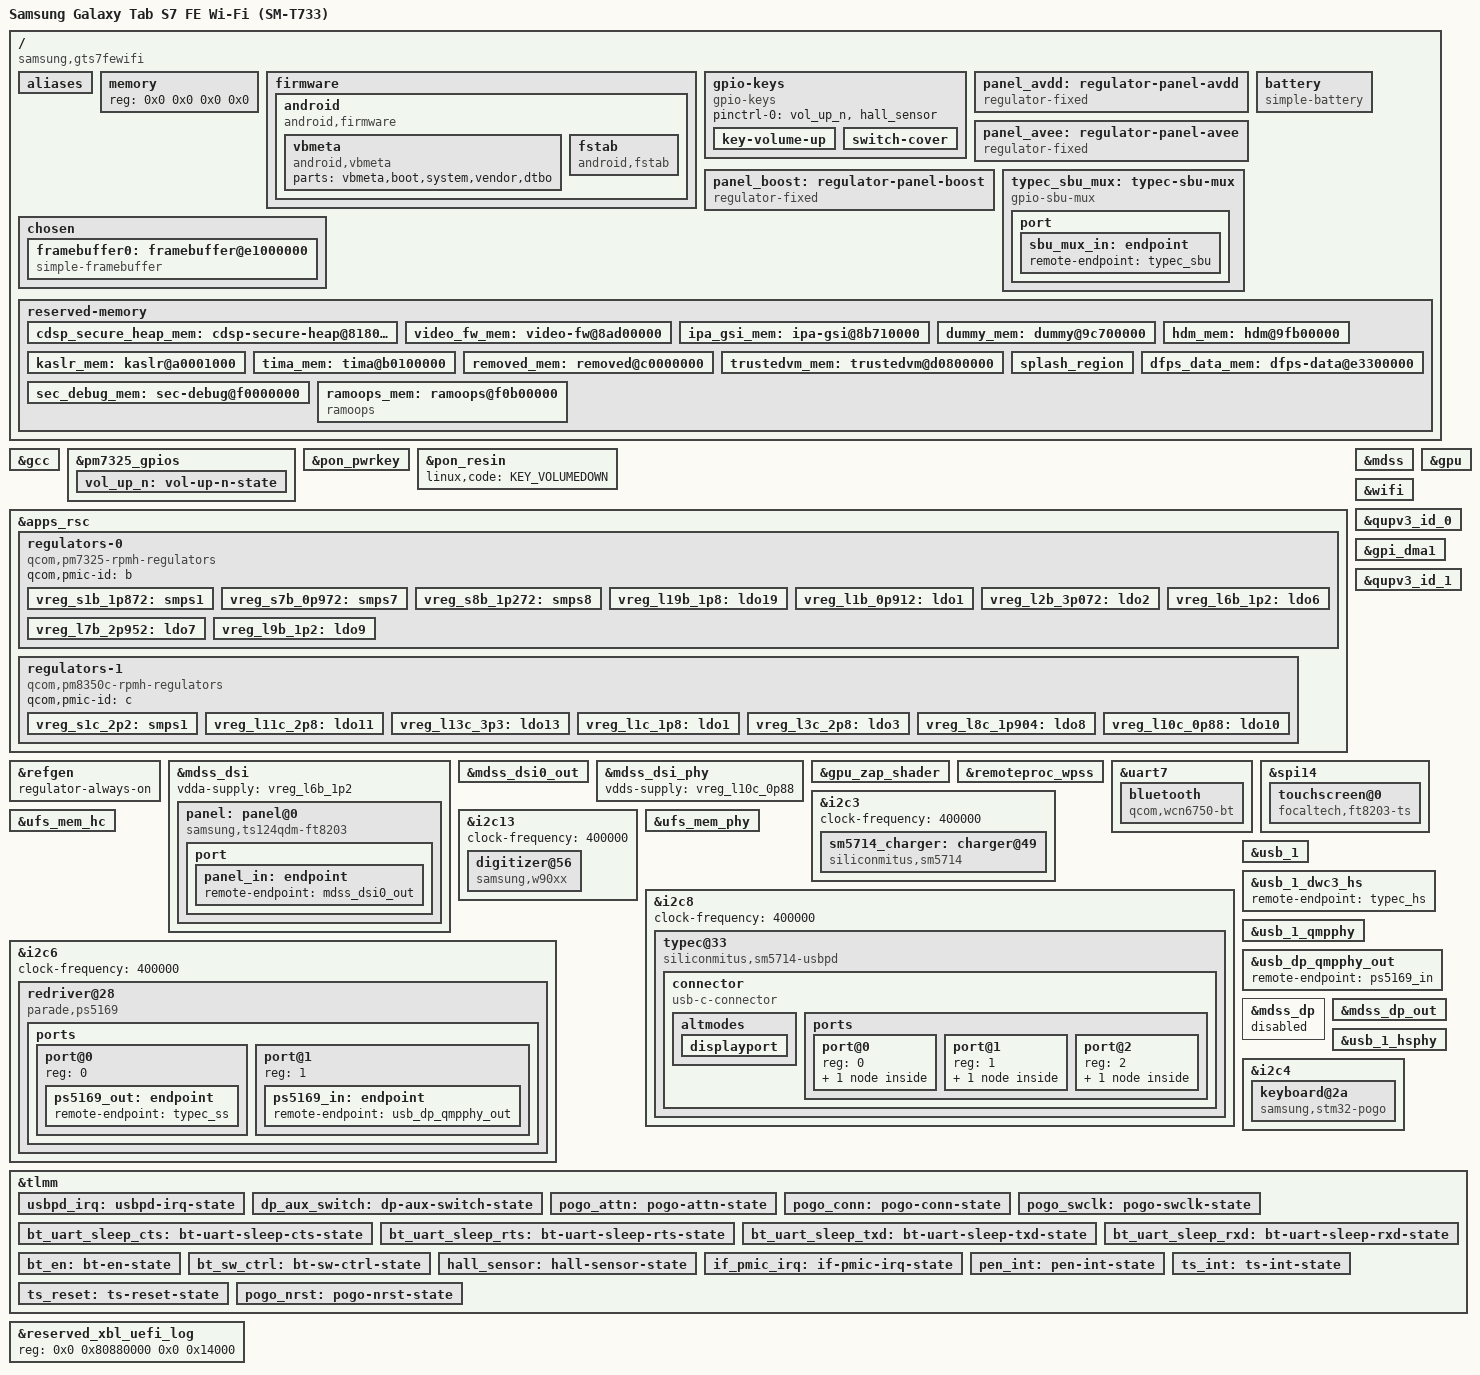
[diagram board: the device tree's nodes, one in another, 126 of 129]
// SPDX-License-Identifier: BSD-3-Clause
/*
 * Samsung Galaxy Tab S7 FE Wi-Fi (SM-T733, "gts7fewifi"), Snapdragon 778G
 * (SM7325, Qualcomm's "yupik").
 *
 * Bring-up: the kernel log on the display the bootloader left on
 * (simple-framebuffer, ramoops), the buttons, (stage 2) the regulators,
 * UFS storage, USB in device mode and the Book Cover Keyboard, and (stage 4)
 * the display driven by msm (its panel, a TS124QDM with a FocalTech FT8203,
 * and the brightness) and the touchscreen, (stage 6) Wi-Fi and Bluetooth
 * (WCN6750), (stage 5) battery and charging, (stage 7) the GPU and
 * (stage 8) the S Pen and the cover's hall sensor. USB-C dual role and
 * DisplayPort are wired through SM5714, PS5169 and the SBU GPIO mux.
 * Everything else in sm7325.dtsi stays disabled until its board wiring is
 * known. The Wi-Fi/Bluetooth and GPU wiring is the same as on the other
 * SM7325/QCM6490 devices (Nothing Phone (1), Fairphone 5).
 *
 * Values come from the stock firmware T733XXS9DYF1 (scripts/inspect-stock.sh):
 * the base tree in vendor_boot.img and Samsung's board overlay in dtbo.img
 * ("Samsung GTS7FEWIFI PROJECT").
 */

/dts-v1/;

#include <dt-bindings/arm/qcom,ids.h>
#include <dt-bindings/gpio/gpio.h>
#include <dt-bindings/input/input.h>
#include <dt-bindings/pinctrl/qcom,pmic-gpio.h>
#include <dt-bindings/regulator/qcom,rpmh-regulator.h>
#include <dt-bindings/usb/pd.h>

#include "sm7325.dtsi"
#include "pm7325.dtsi"
#include "pmk8350.dtsi" /* PMK7325 */

/ {
	model = "Samsung Galaxy Tab S7 FE Wi-Fi (SM-T733)";
	compatible = "samsung,gts7fewifi", "qcom,sm7325";
	chassis-type = "tablet";

	/*
	 * The bootloader picks the tree by these. The same as the stock base
	 * tree ("Yupik SoC"): SM7325 and SoC id 0x203, a variant mainline's
	 * qcom,ids.h has no name for; board-id 0 0 as the base tree has (the
	 * board's own <0x22 rev> are in the dtbo overlays, which jk_os keeps
	 * empty: targets/devices/tablet/samsung-gts7fe/dtbo). dtbo-version, as
	 * the stock base tree has it, matches the overlays'.
	 */
	qcom,msm-id = <QCOM_ID_SM7325 0x10000>, <0x203 0x10000>;
	qcom,board-id = <0 0>;
	dtbo-version = <0>;

	/*
	 * Nodes Samsung's bootloader updates before starting the kernel, under
	 * the names it looks them up by (its strings: "/memory",
	 * "/firmware/android/fstab"), as stock's tree has them. With
	 * mainline's (memory@80000000, no android node) our tree fell back to
	 * Download mode where stock's didn't. It fills in the memory size.
	 */
	/delete-node/ memory@80000000;

	/*
	 * Bluetooth's UART needs a line number, which qcom_geni_serial takes
	 * from its serial alias ("Invalid line -19" without it).
	 */
	aliases {
		bluetooth0 = &bluetooth;
		serial1 = &uart7;
		wifi0 = &wifi;
	};

	memory {
		device_type = "memory";
		reg = <0x0 0x0 0x0 0x0>;
	};

	firmware {
		android {
			compatible = "android,firmware";

			vbmeta {
				compatible = "android,vbmeta";
				parts = "vbmeta,boot,system,vendor,dtbo";
			};

			fstab {
				compatible = "android,fstab";
			};
		};
	};

	/*
	 * Volume up, as stock has it (Samsung's gpio_keys: PM7325 GPIO 6,
	 * active low). Volume down and power are the PMIC's own keys (PON
	 * resin and pwrkey, below). U-Boot's menu uses all three.
	 */
	gpio-keys {
		compatible = "gpio-keys";
		pinctrl-0 = <&vol_up_n>, <&hall_sensor>;
		pinctrl-names = "default";

		key-volume-up {
			label = "Volume Up";
			gpios = <&pm7325_gpios 6 GPIO_ACTIVE_LOW>;
			linux,code = <KEY_VOLUMEUP>;
			debounce-interval = <15>;
		};

		/*
		 * The Book Cover's magnet (stock: hall_ic's hall, GPIO 101,
		 * active low, event 0x15 = SW_LID).
		 */
		switch-cover {
			label = "Cover";
			gpios = <&tlmm 101 GPIO_ACTIVE_LOW>;
			linux,input-type = <EV_SW>;
			linux,code = <SW_LID>;
			linux,can-disable;
			debounce-interval = <150>;
			wakeup-source;
		};
	};

	/*
	 * The panel's bias rails (stock: Samsung's fixed_regulator nodes, GPIO
	 * enables): panel_buck_en and panel_buck_en2 switch the ISL98608 that
	 * makes the TFT's positive and negative supplies, panel_boost_en the
	 * MAX77816 behind the backlight. The bootloader sets those chips up
	 * over I2C and switches the rails on; switching them off would lose
	 * that setup (msm's display off then hangs the DSI link), so they stay
	 * on, and the panel only sleeps when the display is off.
	 */
	panel_avdd: regulator-panel-avdd {
		compatible = "regulator-fixed";
		regulator-name = "panel_avdd";
		gpio = <&tlmm 96 GPIO_ACTIVE_HIGH>;
		enable-active-high;
		regulator-boot-on;
		regulator-always-on;
	};

	panel_avee: regulator-panel-avee {
		compatible = "regulator-fixed";
		regulator-name = "panel_avee";
		gpio = <&tlmm 97 GPIO_ACTIVE_HIGH>;
		enable-active-high;
		regulator-boot-on;
		regulator-always-on;
	};

	panel_boost: regulator-panel-boost {
		compatible = "regulator-fixed";
		regulator-name = "panel_boost";
		gpio = <&tlmm 98 GPIO_ACTIVE_HIGH>;
		enable-active-high;
		regulator-boot-on;
		regulator-always-on;
	};

	/* Stock AUX_EN_N GPIO100 and AUX_SEL GPIO99. */
	typec_sbu_mux: typec-sbu-mux {
		compatible = "gpio-sbu-mux";
		enable-gpios = <&tlmm 100 GPIO_ACTIVE_LOW>;
		select-gpios = <&tlmm 99 GPIO_ACTIVE_HIGH>;
		pinctrl-names = "default";
		pinctrl-0 = <&dp_aux_switch>;
		orientation-switch;
		mode-switch;

		port {
			sbu_mux_in: endpoint {
				remote-endpoint = <&typec_sbu>;
			};
		};
	};

	/* Stock sm5714-fuelgauge / sec-battery values. */
	battery: battery {
		compatible = "simple-battery";
		device-chemistry = "lithium-ion";
		charge-full-design-microamp-hours = <10090000>;
		constant-charge-voltage-max-microvolt = <4380000>;
	};

	chosen {
		#address-cells = <2>;
		#size-cells = <2>;
		ranges;

		/*
		 * The bootloader's splash buffer (stock splash_region), which it
		 * keeps scanning out to the panel: 1600x2560 portrait (Samsung's
		 * ss_dsi_panel_*_WQXGA, 0x640 x 0xa00). The kernel log shows here
		 * until msm takes the display over.
		 */
		framebuffer0: framebuffer@e1000000 {
			compatible = "simple-framebuffer";
			reg = <0x0 0xe1000000 0x0 (1600 * 2560 * 4)>;
			width = <1600>;
			height = <2560>;
			stride = <(1600 * 4)>;
			format = "a8r8g8b8";
			/*
			 * No clocks or power domain: simpledrm would wait for the
			 * display clock driver to probe before showing anything.
			 * clk_ignore_unused / pd_ignore_unused (DEVICE_CMDLINE)
			 * keep them on meanwhile.
			 */
		};
	};

	/*
	 * Memory the firmware uses that kodiak.dtsi doesn't reserve (or
	 * reserves smaller), from the stock base tree and Samsung's overlay.
	 * The kernel touching any of it can reset the SoC.
	 */
	reserved-memory {
		cdsp_secure_heap_mem: cdsp-secure-heap@81800000 {
			reg = <0x0 0x81800000 0x0 0x1e00000>;
			no-map;
		};

		video_fw_mem: video-fw@8ad00000 {
			reg = <0x0 0x8ad00000 0x0 0x500000>;
			no-map;
		};

		ipa_gsi_mem: ipa-gsi@8b710000 {
			reg = <0x0 0x8b710000 0x0 0xa000>;
			no-map;
		};

		dummy_mem: dummy@9c700000 {
			reg = <0x0 0x9c700000 0x0 0x100000>;
			no-map;
		};

		hdm_mem: hdm@9fb00000 {
			reg = <0x0 0x9fb00000 0x0 0x1000>;
			no-map;
		};

		kaslr_mem: kaslr@a0001000 {
			reg = <0x0 0xa0001000 0x0 0x1000>;
			no-map;
		};

		tima_mem: tima@b0100000 {
			reg = <0x0 0xb0100000 0x0 0x100000>;
			no-map;
		};

		removed_mem: removed@c0000000 {
			reg = <0x0 0xc0000000 0x0 0x5100000>;
			no-map;
		};

		/* pil_trustedvm_region, qrtr-shmem and the two neuron blocks. */
		trustedvm_mem: trustedvm@d0800000 {
			reg = <0x0 0xd0800000 0x0 0x7800000>;
			no-map;
		};

		/*
		 * Named as stock names it: Samsung's bootloader keeps the display
		 * running for the kernel only if this region is called exactly
		 * splash_region (see sm8450-samsung-r0q.dts).
		 */
		splash_region: splash_region {
			reg = <0x0 0xe1000000 0x0 0x2300000>;
			no-map;
		};

		dfps_data_mem: dfps-data@e3300000 {
			reg = <0x0 0xe3300000 0x0 0x100000>;
			no-map;
		};

		/* Samsung's debug log (sec_debug) and platform log (ss_plog). */
		sec_debug_mem: sec-debug@f0000000 {
			reg = <0x0 0xf0000000 0x0 0xb00000>;
			no-map;
		};

		ramoops_mem: ramoops@f0b00000 {
			compatible = "ramoops";
			reg = <0x0 0xf0b00000 0x0 0x100000>;
			record-size = <0x40000>;
			console-size = <0x40000>;
			ftrace-size = <0x40000>;
			pmsg-size = <0x40000>;
		};
	};
};

/*
 * GCC clocks the firmware keeps for itself (modem, Wi-Fi subsystem, QSPI,
 * security): touching their registers freezes the CPU. The kernel hung
 * registering GCC's clocks without this; the same list as the other
 * SM7325/QCM6490 phones (the Fairphone 5's, the longest).
 */
&gcc {
	protected-clocks = <GCC_CFG_NOC_LPASS_CLK>,
			   <GCC_EDP_CLKREF_EN>,
			   <GCC_MSS_CFG_AHB_CLK>,
			   <GCC_MSS_GPLL0_MAIN_DIV_CLK_SRC>,
			   <GCC_MSS_OFFLINE_AXI_CLK>,
			   <GCC_MSS_Q6SS_BOOT_CLK_SRC>,
			   <GCC_MSS_Q6_MEMNOC_AXI_CLK>,
			   <GCC_MSS_SNOC_AXI_CLK>,
			   <GCC_QSPI_CNOC_PERIPH_AHB_CLK>,
			   <GCC_QSPI_CORE_CLK>,
			   <GCC_QSPI_CORE_CLK_SRC>,
			   <GCC_SEC_CTRL_CLK_SRC>,
			   <GCC_WPSS_AHB_BDG_MST_CLK>,
			   <GCC_WPSS_AHB_CLK>,
			   <GCC_WPSS_RSCP_CLK>;
};

&pm7325_gpios {
	vol_up_n: vol-up-n-state {
		pins = "gpio6";
		function = PMIC_GPIO_FUNC_NORMAL;
		bias-pull-up;
		input-enable;
		power-source = <1>;
	};
};

&pon_pwrkey {
	status = "okay";
};

&pon_resin {
	linux,code = <KEY_VOLUMEDOWN>;
	status = "okay";
};

/*
 * The RPMh regulators stage 2 uses, at the voltages stock sets them to
 * (Samsung's rpmh-regulator nodes, qcom,init-voltage): fixed, so the
 * regulator core applies them as it registers each one.
 */
&apps_rsc {
	regulators-0 {
		compatible = "qcom,pm7325-rpmh-regulators";
		qcom,pmic-id = "b";

		/*
		 * The WCN6750's supplies (stock: its bt_wcn6750 and qcom,wcn6750
		 * nodes): S1B 1.872 V, S7B 0.972 V, S8B 1.27 V, L19B 1.8 V;
		 * ranges as on the Fairphone 5.
		 */
		vreg_s1b_1p872: smps1 {
			regulator-name = "vreg_s1b_1p872";
			regulator-min-microvolt = <1840000>;
			regulator-max-microvolt = <2040000>;
		};

		vreg_s7b_0p972: smps7 {
			regulator-name = "vreg_s7b_0p972";
			regulator-min-microvolt = <535000>;
			regulator-max-microvolt = <1120000>;
		};

		vreg_s8b_1p272: smps8 {
			regulator-name = "vreg_s8b_1p272";
			regulator-min-microvolt = <1200000>;
			regulator-max-microvolt = <1500000>;
			regulator-initial-mode = <RPMH_REGULATOR_MODE_RET>;
		};

		vreg_l19b_1p8: ldo19 {
			regulator-name = "vreg_l19b_1p8";
			regulator-min-microvolt = <1800000>;
			regulator-max-microvolt = <2000000>;
			regulator-initial-mode = <RPMH_REGULATOR_MODE_HPM>;
		};

		/* USB3/DP combo PLL: stock PM7325 L1, 0.912 V. */
		vreg_l1b_0p912: ldo1 {
			regulator-name = "vreg_l1b_0p912";
			regulator-min-microvolt = <912000>;
			regulator-max-microvolt = <912000>;
			regulator-initial-mode = <RPMH_REGULATOR_MODE_HPM>;
		};

		/* USB 2.0 PHY, 3.1 V */
		vreg_l2b_3p072: ldo2 {
			regulator-name = "vreg_l2b_3p072";
			regulator-min-microvolt = <3072000>;
			regulator-max-microvolt = <3072000>;
			regulator-initial-mode = <RPMH_REGULATOR_MODE_HPM>;
		};

		/*
		 * UFS PHY PLL, and the display's DSI controller (stock:
		 * vdda-1p2-supply). Always on: while the display ran on the
		 * bootloader's setup alone, the regulator core switched it off
		 * once UFS or USB let go of it (the screen flickered and went
		 * black). Fixed in high power mode too: with UFS's load allowed
		 * to set it, it dropped to low power mode whenever the UFS PHY
		 * was idle.
		 */
		vreg_l6b_1p2: ldo6 {
			regulator-name = "vreg_l6b_1p2";
			regulator-min-microvolt = <1200000>;
			regulator-max-microvolt = <1200000>;
			regulator-initial-mode = <RPMH_REGULATOR_MODE_HPM>;
			regulator-always-on;
			regulator-boot-on;
		};

		/* UFS VCC (and the SD card slot, not used yet) */
		vreg_l7b_2p952: ldo7 {
			regulator-name = "vreg_l7b_2p952";
			regulator-min-microvolt = <2952000>;
			regulator-max-microvolt = <2952000>;
			regulator-initial-mode = <RPMH_REGULATOR_MODE_HPM>;
			regulator-allow-set-load;
			regulator-allowed-modes = <RPMH_REGULATOR_MODE_LPM
						   RPMH_REGULATOR_MODE_HPM>;
		};

		/* UFS VCCQ */
		vreg_l9b_1p2: ldo9 {
			regulator-name = "vreg_l9b_1p2";
			regulator-min-microvolt = <1200000>;
			regulator-max-microvolt = <1200000>;
			regulator-initial-mode = <RPMH_REGULATOR_MODE_HPM>;
			regulator-allow-set-load;
			regulator-allowed-modes = <RPMH_REGULATOR_MODE_LPM
						   RPMH_REGULATOR_MODE_HPM>;
		};
	};

	regulators-1 {
		compatible = "qcom,pm8350c-rpmh-regulators";
		qcom,pmic-id = "c";

		/* The WCN6750's 2.2 V (stock pm8350c_s1) and 2.8 V (pm8350c_l11). */
		vreg_s1c_2p2: smps1 {
			regulator-name = "vreg_s1c_2p2";
			regulator-min-microvolt = <2190000>;
			regulator-max-microvolt = <2210000>;
			regulator-initial-mode = <RPMH_REGULATOR_MODE_HPM>;
		};

		vreg_l11c_2p8: ldo11 {
			regulator-name = "vreg_l11c_2p8";
			regulator-min-microvolt = <2800000>;
			regulator-max-microvolt = <3544000>;
			regulator-initial-mode = <RPMH_REGULATOR_MODE_HPM>;
		};

		/*
		 * The S Pen digitizer (stock: pm8350c_l13, 3.3 V). The PLDO steps
		 * are 1.504 V + n * 8 mV, so 3.3 V itself can't be set (and a
		 * value off the grid fails the whole PMIC's regulators): 3.304 V.
		 */
		vreg_l13c_3p3: ldo13 {
			regulator-name = "vreg_l13c_3p3";
			regulator-min-microvolt = <3304000>;
			regulator-max-microvolt = <3304000>;
			regulator-initial-mode = <RPMH_REGULATOR_MODE_HPM>;
			regulator-boot-on;
		};

		/* USB 2.0 PHY, 1.8 V */
		vreg_l1c_1p8: ldo1 {
			regulator-name = "vreg_l1c_1p8";
			regulator-min-microvolt = <1800000>;
			regulator-max-microvolt = <1800000>;
			regulator-initial-mode = <RPMH_REGULATOR_MODE_HPM>;
		};

		/* The keyboard MCU (stock: stm32_vddo-supply) */
		vreg_l3c_2p8: ldo3 {
			regulator-name = "vreg_l3c_2p8";
			regulator-min-microvolt = <2800000>;
			regulator-max-microvolt = <2800000>;
			regulator-initial-mode = <RPMH_REGULATOR_MODE_HPM>;
		};

		/*
		 * The panel's I/O supply (stock: panel_ldo_en, 1.904 V). On for
		 * good, like the bias rails.
		 */
		vreg_l8c_1p904: ldo8 {
			regulator-name = "vreg_l8c_1p904";
			regulator-min-microvolt = <1904000>;
			regulator-max-microvolt = <1904000>;
			regulator-initial-mode = <RPMH_REGULATOR_MODE_HPM>;
			regulator-always-on;
			regulator-boot-on;
		};

		/*
		 * USB 2.0 PHY core, UFS PHY, and the display's DSI PHY (stock:
		 * vdda-0p9-supply): always on and in high power mode, like L6B.
		 */
		vreg_l10c_0p88: ldo10 {
			regulator-name = "vreg_l10c_0p88";
			regulator-min-microvolt = <880000>;
			regulator-max-microvolt = <880000>;
			regulator-initial-mode = <RPMH_REGULATOR_MODE_HPM>;
			regulator-always-on;
			regulator-boot-on;
		};
	};
};

/*
 * The reference voltage of the display's DSI controller (its refgen-supply),
 * which the bootloader left on. While nothing claimed it (the display on the
 * bootloader's setup alone), the regulator core switched it off 30 s after
 * boot as unused: the screen went black. Kept on in case msm doesn't come up.
 */
&refgen {
	regulator-always-on;
};

/*
 * The display: one DSI link, 4 lanes, to the 12.4" 1600x2560 TS124QDM panel
 * with a FocalTech FT8203 (Samsung: ss_dsi_panel_FT8203_TS124QDM_WQXGA), as
 * on the Fairphone 5 (same SoC family, same supplies and reset GPIO). The
 * stock overlay also lists a CSOT panel with a Himax HX83121; GPIO 80 tells
 * them apart (stock: vendor_check-gpio) and reads high, FocalTech, here.
 */
&mdss {
	status = "okay";
};

&mdss_dsi {
	vdda-supply = <&vreg_l6b_1p2>;

	status = "okay";

	panel: panel@0 {
		compatible = "samsung,ts124qdm-ft8203";
		reg = <0>;

		reset-gpios = <&tlmm 44 GPIO_ACTIVE_LOW>;

		vddi-supply = <&vreg_l8c_1p904>;
		avdd-supply = <&panel_avdd>;
		avee-supply = <&panel_avee>;

		/*
		 * Mounted portrait; the tablet is used landscape with the
		 * Book Cover Keyboard below the screen, which puts the panel's
		 * top on the left (fbcon=rotate:1 before this).
		 */
		rotation = <270>;

		port {
			panel_in: endpoint {
				remote-endpoint = <&mdss_dsi0_out>;
			};
		};
	};
};

&mdss_dsi0_out {
	data-lanes = <0 1 2 3>;
	remote-endpoint = <&panel_in>;
};

&mdss_dsi_phy {
	vdds-supply = <&vreg_l10c_0p88>;

	status = "okay";
};

/*
 * The GPU, Adreno 642L. Its firmware: a660_sqe.fw and a660_gmu.bin from the
 * stock vendor partition (DEVICE_STOCK_FIRMWARE), the zap shader from the
 * stock apnhlos partition, which the system mounts (S06firmware) before
 * anything opens the GPU.
 */
&gpu {
	status = "okay";
};

&gpu_zap_shader {
	firmware-name = "qcom/sm7325/samsung/gts7fewifi/apnhlos/image/a660_zap.mdt";
};

/*
 * Wi-Fi: the WCN6750, run by the WPSS remote processor (firmware from the
 * stock vendor partition). The system loads it once its files are there
 * (/etc/init.d/S07wireless): at boot, before the system is mounted, they
 * aren't.
 */
&remoteproc_wpss {
	firmware-name = "qcom/sm7325/samsung/gts7fewifi/wpss.mdt";
	status = "okay";
};

&wifi {
	status = "okay";
};

/*
 * Bluetooth: the WCN6750's, on QUP SE7's UART (stock: bt_wcn6750, enable
 * GPIO 85, sw_ctrl GPIO 86), as on the Nothing Phone (1).
 */
&qupv3_id_0 {
	status = "okay";
};

&uart7 {
	/delete-property/ interrupts;
	interrupts-extended = <&intc GIC_SPI 608 IRQ_TYPE_LEVEL_HIGH>,
			      <&tlmm 31 IRQ_TYPE_EDGE_FALLING>;

	pinctrl-1 = <&bt_uart_sleep_cts>, <&bt_uart_sleep_rts>,
		    <&bt_uart_sleep_txd>, <&bt_uart_sleep_rxd>;
	pinctrl-names = "default", "sleep";

	status = "okay";

	bluetooth: bluetooth {
		compatible = "qcom,wcn6750-bt";

		pinctrl-0 = <&bt_en>, <&bt_sw_ctrl>;
		pinctrl-names = "default";

		enable-gpios = <&tlmm 85 GPIO_ACTIVE_HIGH>;
		swctrl-gpios = <&tlmm 86 GPIO_ACTIVE_HIGH>;

		vddio-supply = <&vreg_l19b_1p8>;
		vddaon-supply = <&vreg_s7b_0p972>;
		vddbtcxmx-supply = <&vreg_s7b_0p972>;
		vddrfacmn-supply = <&vreg_s7b_0p972>;
		vddrfa0p8-supply = <&vreg_s7b_0p972>;
		vddrfa1p7-supply = <&vreg_s1b_1p872>;
		vddrfa1p2-supply = <&vreg_s8b_1p272>;
		vddrfa2p2-supply = <&vreg_s1c_2p2>;
		vddasd-supply = <&vreg_l11c_2p8>;
		max-speed = <3200000>;
	};
};

/*
 * The touchscreen: the FT8203's touch half, on QUP SE14's SPI bus (stock:
 * focaltech@1 on qupv3_se16_spi, pins GPIO 56-59), interrupt on GPIO 81,
 * reset on GPIO 50. It has no flash: the driver loads its firmware (from the
 * stock vendor partition, DEVICE_STOCK_FIRMWARE) every time the panel powers
 * up, so it follows the panel.
 */
&gpi_dma1 {
	status = "okay";
};

&qupv3_id_1 {
	status = "okay";
};

&spi14 {
	status = "okay";

	touchscreen@0 {
		compatible = "focaltech,ft8203-ts";
		reg = <0>;
		spi-max-frequency = <6000000>;

		interrupts-extended = <&tlmm 81 IRQ_TYPE_EDGE_FALLING>;
		reset-gpios = <&tlmm 50 GPIO_ACTIVE_LOW>;

		firmware-name = "tsp_focaltech/ft8203_gts7xllite.bin";
		panel = <&panel>;

		pinctrl-0 = <&ts_int>, <&ts_reset>;
		pinctrl-names = "default";

		touchscreen-size-x = <1600>;
		touchscreen-size-y = <2560>;
	};
};

/*
 * Battery and charging: Silicon Mitus SM5714 (stock: sm5714@49 on
 * qupv3_se3_i2c, interrupt GPIO 54), charger at 0x49, fuel gauge at 0x71
 * (reached by the same driver, patches/0006). Its USB-PD/Type-C block
 * (usbpd-sm5714@33 on i2c8) owns role switching and the negotiated 5 V
 * input limit; the charger owns the MUIC data switch and OTG boost.
 */
&i2c3 {
	clock-frequency = <400000>;
	status = "okay";

	sm5714_charger: charger@49 {
		compatible = "siliconmitus,sm5714";
		siliconmitus,typec-controlled;
		reg = <0x49>;

		interrupts-extended = <&tlmm 54 IRQ_TYPE_LEVEL_LOW>;
		pinctrl-0 = <&if_pmic_irq>;
		pinctrl-names = "default";

		monitored-battery = <&battery>;
	};
};

/*
 * The S Pen digitizer, a Wacom W9021 (stock: wacom@56, "wacom,w90xx", on
 * qupv3_se13_i2c), interrupt on GPIO 39, firmware-update enable on GPIO 38.
 * Stock wacom,invert = <1 0 1>: the chip's x inverted, then x and y swapped.
 */
&i2c13 {
	clock-frequency = <400000>;
	status = "okay";

	digitizer@56 {
		compatible = "samsung,w90xx";
		reg = <0x56>;

		interrupts-extended = <&tlmm 39 IRQ_TYPE_LEVEL_LOW>;
		fwe-gpios = <&tlmm 38 GPIO_ACTIVE_HIGH>;
		avdd-supply = <&vreg_l13c_3p3>;

		pinctrl-0 = <&pen_int>;
		pinctrl-names = "default";

		touchscreen-inverted-x;
		touchscreen-swapped-x-y;
		touchscreen-x-mm = <166>;
		touchscreen-y-mm = <266>;
	};
};

/* UFS storage, wired as stock has it (reset on GPIO 175). */
&ufs_mem_hc {
	reset-gpios = <&tlmm 175 GPIO_ACTIVE_LOW>;

	vcc-supply = <&vreg_l7b_2p952>;
	vcc-max-microamp = <800000>;
	vccq-supply = <&vreg_l9b_1p2>;
	vccq-max-microamp = <900000>;

	status = "okay";
};

&ufs_mem_phy {
	vdda-phy-supply = <&vreg_l10c_0p88>;
	vdda-pll-supply = <&vreg_l6b_1p2>;

	status = "okay";
};

/*
 * The connector's HS link controls DWC3 roles. The SS link passes through
 * the PS5169 to the QMP USB3/DP PHY; SBU orientation is a separate switch.
 * Keep the gadget registered: the UDC core rebinds it on return to device mode.
 */
&i2c8 {
	clock-frequency = <400000>;
	status = "okay";

	typec@33 {
		compatible = "siliconmitus,sm5714-usbpd";
		reg = <0x33>;
		interrupts-extended = <&tlmm 142 IRQ_TYPE_LEVEL_LOW>;
		pinctrl-names = "default";
		pinctrl-0 = <&usbpd_irq>;
		power-supplies = <&sm5714_charger>;

		connector {
			compatible = "usb-c-connector";
			label = "USB-C";
			power-role = "dual";
			data-role = "dual";
			try-power-role = "sink";
			/* Limit bring-up to fixed 5 V, within the existing charger path. */
			source-pdos = <PDO_FIXED(5000, 500, PDO_FIXED_DUAL_ROLE |
						PDO_FIXED_DATA_SWAP | PDO_FIXED_USB_COMM)>;
			sink-pdos = <PDO_FIXED(5000, 3000, PDO_FIXED_DUAL_ROLE |
					      PDO_FIXED_DATA_SWAP | PDO_FIXED_USB_COMM)>;
			op-sink-microwatt = <2500000>;

			altmodes {
				displayport {
					svid = /bits/ 16 <0xff01>;
					/* DP source, receptacle, assignments C/D/E. */
					vdo = <0x00001c46>;
				};
			};

			ports {
				#address-cells = <1>;
				#size-cells = <0>;
				port@0 {
					reg = <0>;
					typec_hs: endpoint {
						remote-endpoint = <&usb_1_dwc3_hs>;
					};
				};
				port@1 {
					reg = <1>;
					typec_ss: endpoint {
						remote-endpoint = <&ps5169_out>;
					};
				};
				port@2 {
					reg = <2>;
					typec_sbu: endpoint {
						remote-endpoint = <&sbu_mux_in>;
					};
				};
			};
		};
	};
};

&i2c6 {
	clock-frequency = <400000>;
	status = "okay";

	redriver@28 {
		compatible = "parade,ps5169";
		reg = <0x28>;
		orientation-switch;
		mode-switch;
		parade,usb-controller = <&usb_1>;
		aux-pullup-supply = <&vreg_l2b_3p072>;
		/* Samsung SM7325 WORK_MODE tuning, not the SM8550 values. */
		parade,reg50 = <0x20>;
		parade,reg51 = <0x40>;
		parade,reg54 = <0x00>;
		parade,reg5d = <0x44>;

		ports {
			#address-cells = <1>;
			#size-cells = <0>;
			port@0 {
				reg = <0>;
				ps5169_out: endpoint {
					remote-endpoint = <&typec_ss>;
				};
			};
			port@1 {
				reg = <1>;
				ps5169_in: endpoint {
					remote-endpoint = <&usb_dp_qmpphy_out>;
				};
			};
		};
	};
};

&usb_1 {
	dr_mode = "otg";
	usb-role-switch;
	status = "okay";
};

&usb_1_dwc3_hs {
	remote-endpoint = <&typec_hs>;
};

&usb_1_qmpphy {
	vdda-phy-supply = <&vreg_l6b_1p2>;
	vdda-pll-supply = <&vreg_l1b_0p912>;
	orientation-switch;
	mode-switch;
	status = "okay";
};

&usb_dp_qmpphy_out {
	remote-endpoint = <&ps5169_in>;
};

/*
 * Off until USB host is confirmed on the device: msm binds the panel only
 * once every enabled display interface has probed, and DP waits for its
 * whole bridge chain (QMP PHY, PS5169, SM5714's connector). Any link that
 * fails to probe would leave the tablet's own screen without a driver.
 */
&mdss_dp {
	vdda-1p2-supply = <&vreg_l6b_1p2>;
	vdda-0p9-supply = <&vreg_l1b_0p912>;
	status = "disabled";
};

&mdss_dp_out {
	data-lanes = <0 1 2 3>;
	link-frequencies = /bits/ 64 <1620000000 2700000000 5400000000>;
};

&usb_1_hsphy {
	vdda-pll-supply = <&vreg_l10c_0p88>;
	vdda18-supply = <&vreg_l1c_1p8>;
	vdda33-supply = <&vreg_l2b_3p072>;

	status = "okay";
};

/*
 * The Book Cover Keyboard: the pogo pins end at an STM32 MCU in the tablet,
 * on QUP SE4's I2C bus at 0x2a (stock: stm32@2a on qupv3_se4_i2c; the QUP
 * is enabled with Bluetooth's UART above). conn
 * (GPIO 21) goes high when a keyboard is attached, the MCU signals events
 * on attn (GPIO 51, level low), nrst (GPIO 45) resets it.
 */
&i2c4 {
	status = "okay";

	keyboard@2a {
		compatible = "samsung,stm32-pogo";
		reg = <0x2a>;

		vdd-supply = <&vreg_l3c_2p8>;
		conn-gpios = <&tlmm 21 GPIO_ACTIVE_HIGH>;
		attn-gpios = <&tlmm 51 GPIO_ACTIVE_HIGH>;
		nrst-gpios = <&tlmm 45 GPIO_ACTIVE_HIGH>;

		pinctrl-0 = <&pogo_attn>, <&pogo_conn>, <&pogo_swclk>, <&pogo_nrst>;
		pinctrl-names = "default";
	};
};

&tlmm {
	usbpd_irq: usbpd-irq-state {
		pins = "gpio142";
		function = "gpio";
		drive-strength = <8>;
		bias-disable;
		input-enable;
	};

	dp_aux_switch: dp-aux-switch-state {
		pins = "gpio99", "gpio100";
		function = "gpio";
		drive-strength = <8>;
		bias-disable;
	};

	pogo_attn: pogo-attn-state {
		pins = "gpio51";
		function = "gpio";
		drive-strength = <2>;
		bias-disable;
	};

	pogo_conn: pogo-conn-state {
		pins = "gpio21";
		function = "gpio";
		drive-strength = <2>;
		bias-disable;
	};

	/* The MCU's debug clock, held low as stock does. */
	pogo_swclk: pogo-swclk-state {
		pins = "gpio46";
		function = "gpio";
		drive-strength = <2>;
		output-low;
		bias-disable;
	};

	/* Bluetooth's UART while asleep, and its GPIOs (as the Nothing Phone (1)). */
	bt_uart_sleep_cts: bt-uart-sleep-cts-state {
		pins = "gpio28";
		function = "gpio";
		bias-bus-hold;
	};

	bt_uart_sleep_rts: bt-uart-sleep-rts-state {
		pins = "gpio29";
		function = "gpio";
		bias-pull-down;
	};

	bt_uart_sleep_txd: bt-uart-sleep-txd-state {
		pins = "gpio30";
		function = "gpio";
		bias-pull-up;
	};

	bt_uart_sleep_rxd: bt-uart-sleep-rxd-state {
		pins = "gpio31";
		function = "gpio";
		bias-pull-up;
	};

	bt_en: bt-en-state {
		pins = "gpio85";
		function = "gpio";
		output-low;
		bias-disable;
	};

	bt_sw_ctrl: bt-sw-ctrl-state {
		pins = "gpio86";
		function = "gpio";
		bias-pull-down;
	};

	hall_sensor: hall-sensor-state {
		pins = "gpio101";
		function = "gpio";
		drive-strength = <2>;
		bias-disable;
	};

	if_pmic_irq: if-pmic-irq-state {
		pins = "gpio54";
		function = "gpio";
		drive-strength = <2>;
		bias-disable;
	};

	pen_int: pen-int-state {
		pins = "gpio39";
		function = "gpio";
		drive-strength = <2>;
		bias-disable;
	};

	ts_int: ts-int-state {
		pins = "gpio81";
		function = "gpio";
		drive-strength = <2>;
		bias-disable;
	};

	ts_reset: ts-reset-state {
		pins = "gpio50";
		function = "gpio";
		drive-strength = <2>;
		bias-disable;
	};

	pogo_nrst: pogo-nrst-state {
		pins = "gpio45";
		function = "gpio";
		drive-strength = <2>;
		output-high;
		bias-disable;
	};
};

/* Stock xbl_uefi region starts 16 KiB lower than kodiak.dtsi's. */
&reserved_xbl_uefi_log {
	reg = <0x0 0x80880000 0x0 0x14000>;
};
